# S6E2DFxJ register map
Vendor: Cypress; File version: 2.1
CPU: CM4 r0p1, little endian, MPU, FPU, 4 interrupt priority bits
Registers are 32-bit, read-write, reset 0x0 unless marked. A register's access mark holds for its fields unless they carry their own. Offsets are from the block's base; [hi:lo] are bit positions; {n}, {i} and the like mark numbered series.

## I2S0 — I2S
Base 0x4006C000
Same registers: I2S1 0x4006C800
0x00 RXFDAT ro — Receive FIFO Register [BHW]
  [31:0] RXDATA — Words received from the serial bus are written to the receive FIFO
0x04 TXFDAT wo — Transmit FIFO Register [BHW]
  [31:0] TXDATA — The words to be transmitted can be written as long as the transmit FIFO is not full
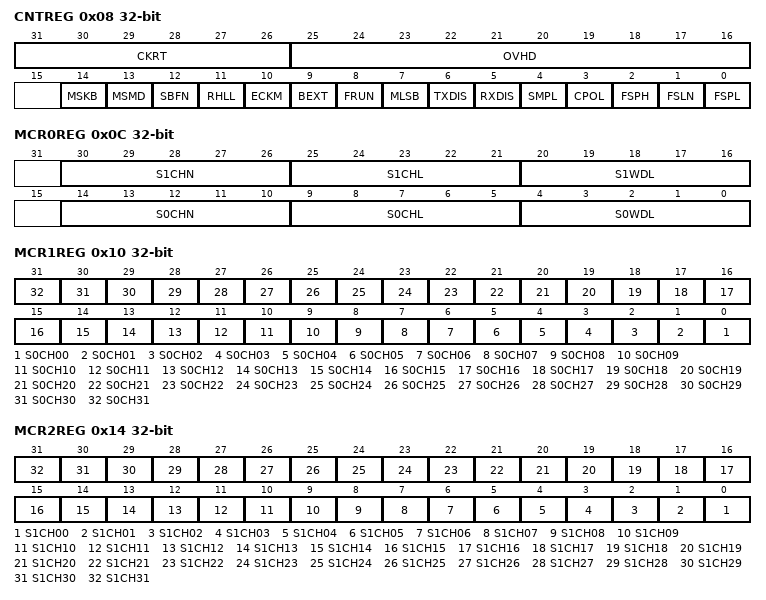
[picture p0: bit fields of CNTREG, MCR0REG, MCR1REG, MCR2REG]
0x08 CNTREG — Control Register [BHW]
  [31:26] CKRT — This bit sets the clock division ratio for output when operating in master mode
  [25:16] OVHD — It can insert OVERHEAD bits to enable adjustment of the frame rate following the valid data of the frame
  [14] MSKB — This sets the serial output data of the invalid transmit frames
  [13] MSMD — This sets master or slave mode
  [12] SBFN — This specifies the subframe configuration (number of subframes) of the frame
  [11] RHLL — This sets the FIFO word configuration to one or two words
  [10] ECKM — This selects the base clock divider in master mode
  [9] BEXT — This sets the upper bit extension mode when the receive word length is smaller than the FIFO word length
  [8] FRUN — This sets the output mode of the frame sync signal
  [7] MLSB — This sets word bit shift order
  [6] TXDIS — This enables or disables the transmit function
  [5] RXDIS — This enables or disables the receive function
  [4] SMPL — This specifies the point where data is sampled
  [3] CPOL — This specifies the I2SCK polarity where drive sampling of the serial data is performed
  [2] FSPH — This specifies the phase for I2SWS frame data
  [1] FSLN — This specifies the pulse width of I2SWS
  [0] FSPL — This sets the polarity of the I2SWS pin
0x0C MCR0REG — Channel Control Register 0 [BHW]
  [30:26] S1CHN — This sets the number of channels for subframe 1
  [25:21] S1CHL — This sets the channel length of the channels that make up subframe 1
  [20:16] S1WDL — This sets the word length of the channels that make up subframe 1
  [14:10] S0CHN — This sets the number of channels for subframe 0
  [9:5] S0CHL — This sets the channel length of the channels that make up subframe 1
  [4:0] S0WDL — This sets the word length of the channels that make up subframe 1
0x10 MCR1REG — Channel Control Register 1 [BHW]
  [n] S0CH{n:02} (n=0..31) — This controls the enable/disable state of the channel {n} in subframe 0
0x14 MCR2REG — Channel Control Register 2 [BHW]
  [n] S1CH{n:02} (n=0..31) — This controls the enable/disable state of the channel {n} in subframe 1
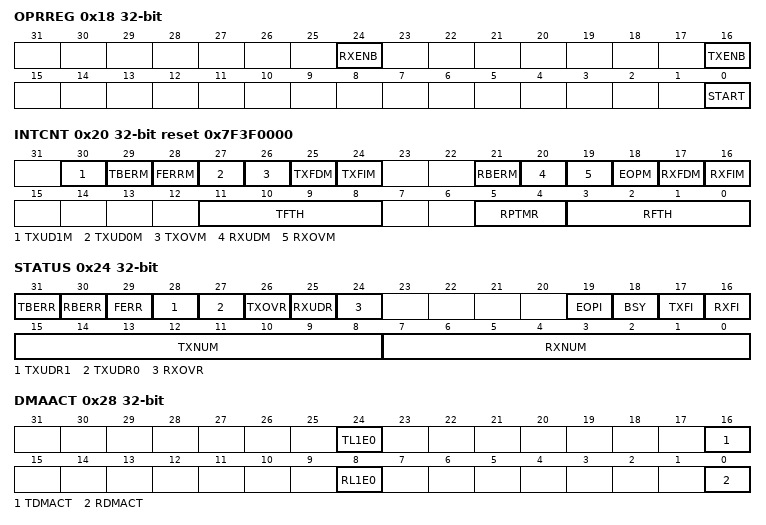
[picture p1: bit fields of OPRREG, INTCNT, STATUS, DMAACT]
0x18 OPRREG — Operation Control Register [BHW]
  [24] RXENB — This sets the enabled/disabled state of the receive operation
  [16] TXENB — This sets the enabled/disabled state of the transmit operation
  [0] START — This enables or disables the I2S interface
0x1C SRST — Soft Reset Register [BHW]
  [0] SRST — Soft reset bit
0x20 INTCNT reset 0x7F3F0000 — Interrupt Control Register [BHW]
  [30] TXUD1M — This bit masks the transmit FIFO underflow interrupt
  [29] TBERM — This bit masks the transmit channel block size error interrupt
  [28] FERRM — This bit masks the frame error interrupt mask
  [27] TXUD0M — This bit masks the transmit FIFO underflow interrupt
  [26] TXOVM — This bit masks the transmit FIFO overflow interrupt
  [25] TXFDM — This bit masks the transmit DMA request
  [24] TXFIM — This bit masks the transmit FIFO interrupt
  [21] RBERM — This bit masks the receive channel block size error interrupt
  [20] RXUDM — This bit masks the receive FIFO underflow interrupt
  [19] RXOVM — This bit masks the receive FIFO overflow interrupt
  [18] EOPM — This bit masks the interrupts by EOPI of the STATUS register
  [17] RXFDM — This bit masks the receive DMA request
  [16] RXFIM — This bit masks the receive FIFO interrupt
  [11:8] TFTH — This bit sets the transmit FIFO threshold value
  [5:4] RPTMR — This is the bit for setting the packet receive completion timer
  [3:0] RFTH — This bit sets the receive FIFO threshold value
0x24 STATUS — Status Register [BHW]
  [31] TBERR ro — This bit is set to 1 if the block size of the DMA transmit channel is set to a value larger than the transmit FIFO threshold value
  [30] RBERR ro — This bit is set to 1 if the block size of the DMA receive channel is set to a value larger than the receive FIFO threshold value
  [29] FERR — This indicates that a frame error has occurred
  [28] TXUDR1 — This is set to 1 when the transmit FIFO underflows at the frame start
  [27] TXUDR0 — This is set to 1 when the transmit FIFO underflows during frame transmission
  [26] TXOVR — This is set to 1 when the transmit FIFO overflows
  [25] RXUDR — This is set to 1 when the receive FIFO underflows
  [24] RXOVR — This is set to 1 when the receive FIFO overflows
  [19] EOPI — This is the interrupt flag based on the receive timer
  [18] BSY ro — This indicates the status of the serial transmit control unit
  [17] TXFI ro — This is set to 1 when the transmit FIFO empty slot meets or exceeds the threshold value
  [16] RXFI ro — This is set to 1 when the receive FIFO data count meets or exceeds the threshold value
  [15:8] TXNUM ro — This indicates the data count in the transmit FIFO
  [7:0] RXNUM ro — This indicates the data count in the receive FIFO
0x28 DMAACT — DMA Startup Register [BHW]
  [24] TL1E0 — This sets the operation mode of TXDREQ
  [16] TDMACT — This bit is enabled when the same register TL1E0=0
  [8] RL1E0 — This sets the operation mode of RXDREQ
  [0] RDMACT — This bit is enabled when the same register RL1E0=0
0x2C TSTREG — Test Register [BHW]
  [0] LBMD — This sets the loopback mode
